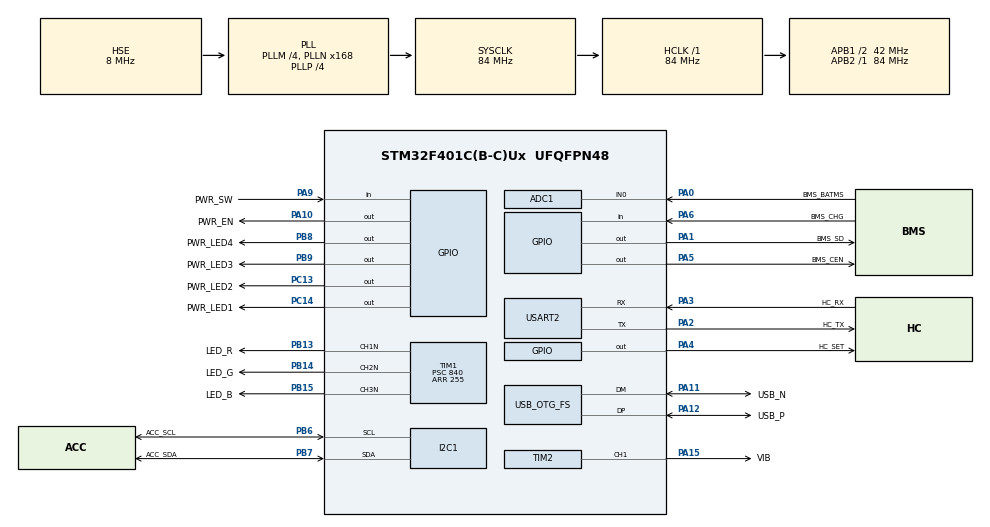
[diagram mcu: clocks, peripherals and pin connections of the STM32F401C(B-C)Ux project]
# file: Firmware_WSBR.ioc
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ADC1.Channel-1\#ChannelRegularConversion=ADC_CHANNEL_0
ADC1.NbrOfConversionFlag=1
ADC1.Rank-1\#ChannelRegularConversion=1
ADC1.SamplingTime-1\#ChannelRegularConversion=ADC_SAMPLETIME_3CYCLES
ADC1.master=1
Mcu.Family=STM32F4
Mcu.Name=STM32F401C(B-C)Ux
Mcu.Package=UFQFPN48
NVIC.PriorityGroup=NVIC_PRIORITYGROUP_4
PA0-WKUP.GPIO_Label=BMS_BATMS
PA0-WKUP.Signal=ADCx_IN0
PA1.GPIO_Label=BMS_SD
PA1.Signal=GPIO_Output
PA10.GPIO_Label=PWR_EN
PA10.Signal=GPIO_Output
PA11.GPIO_Label=USB_N
PA11.Mode=Device_Only
PA11.Signal=USB_OTG_FS_DM
PA12.GPIO_Label=USB_P
PA12.Mode=Device_Only
PA12.Signal=USB_OTG_FS_DP
PA13.GPIO_Label=SW_DIO
PA13.Mode=Trace_Asynchronous_SW
PA13.Signal=SYS_JTMS-SWDIO
PA14.GPIO_Label=SW_CLK
PA14.Mode=Trace_Asynchronous_SW
PA14.Signal=SYS_JTCK-SWCLK
PA15.GPIO_Label=VIB
PA15.Signal=S_TIM2_CH1_ETR
PA2.GPIO_Label=HC_TX
PA2.Mode=Asynchronous
PA2.Signal=USART2_TX
PA3.GPIO_Label=HC_RX
PA3.Mode=Asynchronous
PA3.Signal=USART2_RX
PA4.GPIO_Label=HC_SET
PA4.PinState=GPIO_PIN_SET
PA4.Signal=GPIO_Output
PA5.GPIO_Label=BMS_CEN
PA5.PinState=GPIO_PIN_SET
PA5.Signal=GPIO_Output
PA6.GPIO_Label=BMS_CHG
PA6.GPIO_PuPd=GPIO_PULLUP
PA6.Signal=GPIO_Input
PA9.GPIO_Label=PWR_SW
PA9.GPIO_PuPd=GPIO_PULLDOWN
PA9.Signal=GPIO_Input
PB13.GPIO_Label=LED_R
PB13.Mode=Output Compare1 CH1N
PB13.Signal=TIM1_CH1N
PB14.GPIO_Label=LED_G
PB14.Mode=PWM Generation2 CH2N
PB14.Signal=TIM1_CH2N
PB15.GPIO_Label=LED_B
PB15.Mode=PWM Generation3 CH3N
PB15.Signal=TIM1_CH3N
PB3.GPIO_Label=SW_O
PB3.Mode=Trace_Asynchronous_SW
PB3.Signal=SYS_JTDO-SWO
PB6.GPIO_Label=ACC_SCL
PB6.Mode=I2C
PB6.Signal=I2C1_SCL
PB7.GPIO_Label=ACC_SDA
PB7.Mode=I2C
PB7.Signal=I2C1_SDA
PB8.GPIO_Label=PWR_LED4
PB8.PinState=GPIO_PIN_RESET
PB8.Signal=GPIO_Output
PB9.GPIO_Label=PWR_LED3
PB9.Signal=GPIO_Output
PC13-ANTI_TAMP.GPIO_Label=PWR_LED2
PC13-ANTI_TAMP.PinState=GPIO_PIN_RESET
PC13-ANTI_TAMP.Signal=GPIO_Output
PC14-OSC32_IN.GPIO_Label=PWR_LED1
PC14-OSC32_IN.Signal=GPIO_Output
PH0\ -\ OSC_IN.GPIO_Label=OSC_IN
PH0\ -\ OSC_IN.Mode=HSE-External-Clock-Source
PH0\ -\ OSC_IN.Signal=RCC_OSC_IN
PH1\ -\ OSC_OUT.GPIO_Label=NC1
PH1\ -\ OSC_OUT.Mode=HSE-External-Clock-Source
PH1\ -\ OSC_OUT.Signal=RCC_OSC_OUT
ProjectManager.HeapSize=0x200
ProjectManager.StackSize=0x400
ProjectManager.TargetToolchain=STM32CubeIDE
RCC.48MHZClocksFreq_Value=48000000
RCC.AHBFreq_Value=84000000
RCC.APB1CLKDivider=RCC_HCLK_DIV2
RCC.APB1Freq_Value=42000000
RCC.APB1TimFreq_Value=84000000
RCC.APB2Freq_Value=84000000
RCC.APB2TimFreq_Value=84000000
RCC.CortexFreq_Value=84000000
RCC.HCLKFreq_Value=84000000
RCC.HSE_VALUE=8000000
RCC.HSI_VALUE=16000000
RCC.LSE_VALUE=32768
RCC.PLLM=4
RCC.PLLN=168
RCC.PLLP=RCC_PLLP_DIV4
RCC.PLLQ=7
RCC.SYSCLKFreq_VALUE=84000000
RCC.SYSCLKSource=RCC_SYSCLKSOURCE_PLLCLK
RCC.VCOOutputFreq_Value=336000000
RCC.VDD_VALUE=3.1
SH.ADCx_IN0.0=ADC1_IN0,IN0
SH.S_TIM2_CH1_ETR.0=TIM2_CH1,PWM Generation1 CH1
TIM1.Channel-Output\ Compare1\ CH1N=TIM_CHANNEL_1
TIM1.Channel-PWM\ Generation2\ CH2N=TIM_CHANNEL_2
TIM1.Channel-PWM\ Generation3\ CH3N=TIM_CHANNEL_3
TIM1.Period=255
TIM1.Prescaler=840
TIM2.Channel-PWM\ Generation1\ CH1=TIM_CHANNEL_1
USART2.VirtualMode=VM_ASYNC
USB_OTG_FS.VirtualMode=Device_Only
VP_TIM1_VS_ClockSourceINT.Mode=Internal
VP_TIM2_VS_ClockSourceINT.Mode=Internal
board=custom

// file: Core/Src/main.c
/* USER CODE BEGIN Header */
/**
  ******************************************************************************
  * @file           : main.c
  * @brief          : Main program body
  ******************************************************************************
  * @attention
  *
  * Copyright (c) 2024 STMicroelectronics.
  * All rights reserved.
  *
  * This software is licensed under terms that can be found in the LICENSE file
  * in the root directory of this software component.
  * If no LICENSE file comes with this software, it is provided AS-IS.
  *
  ******************************************************************************
  */
/* USER CODE END Header */
#include "main.h"
#include "adc.h"
#include "i2c.h"
#include "tim.h"
#include "usart.h"
#include "usb_otg.h"
#include "gpio.h"

void SystemClock_Config(void);

int main(void)
{

  /* MCU Configuration--------------------------------------------------------*/

  /* Reset of all peripherals, Initializes the Flash interface and the Systick. */
  HAL_Init();

  /* Configure the system clock */
  SystemClock_Config();

  /* Initialize all configured peripherals */
  MX_GPIO_Init();
  MX_USB_OTG_FS_PCD_Init();
  MX_ADC1_Init();
  MX_I2C1_Init();
  MX_TIM1_Init();
  MX_TIM2_Init();
  MX_USART2_UART_Init();
  /* USER CODE BEGIN 2 */

  usermain();

  /* USER CODE END 2 */

  /* Infinite loop */
  while (1)
  {

  }
}

void SystemClock_Config(void)
{
  RCC_OscInitTypeDef RCC_OscInitStruct = {0};
  RCC_ClkInitTypeDef RCC_ClkInitStruct = {0};

  /** Configure the main internal regulator output voltage
  */
  __HAL_RCC_PWR_CLK_ENABLE();
  __HAL_PWR_VOLTAGESCALING_CONFIG(PWR_REGULATOR_VOLTAGE_SCALE2);

  /** Initializes the RCC Oscillators according to the specified parameters
  * in the RCC_OscInitTypeDef structure.
  */
  RCC_OscInitStruct.OscillatorType = RCC_OSCILLATORTYPE_HSE;
  RCC_OscInitStruct.HSEState = RCC_HSE_BYPASS;
  RCC_OscInitStruct.PLL.PLLState = RCC_PLL_ON;
  RCC_OscInitStruct.PLL.PLLSource = RCC_PLLSOURCE_HSE;
  RCC_OscInitStruct.PLL.PLLM = 4;
  RCC_OscInitStruct.PLL.PLLN = 168;
  RCC_OscInitStruct.PLL.PLLP = RCC_PLLP_DIV4;
  RCC_OscInitStruct.PLL.PLLQ = 7;
  if (HAL_RCC_OscConfig(&RCC_OscInitStruct) != HAL_OK)
  {
    Error_Handler();
  }

  /** Initializes the CPU, AHB and APB buses clocks
  */
  RCC_ClkInitStruct.ClockType = RCC_CLOCKTYPE_HCLK|RCC_CLOCKTYPE_SYSCLK
                              |RCC_CLOCKTYPE_PCLK1|RCC_CLOCKTYPE_PCLK2;
  RCC_ClkInitStruct.SYSCLKSource = RCC_SYSCLKSOURCE_PLLCLK;
  RCC_ClkInitStruct.AHBCLKDivider = RCC_SYSCLK_DIV1;
  RCC_ClkInitStruct.APB1CLKDivider = RCC_HCLK_DIV2;
  RCC_ClkInitStruct.APB2CLKDivider = RCC_HCLK_DIV1;

  if (HAL_RCC_ClockConfig(&RCC_ClkInitStruct, FLASH_LATENCY_2) != HAL_OK)
  {
    Error_Handler();
  }
}

void Error_Handler(void)
{
  __disable_irq();
  while (1)
  {
  }
}
